# Generic_ARMv8MMainline register map
Vendor: ARM Ltd.; Series: ARMv8-M Mainline architecture (Cortex-M33 / Cortex-M35P / Cortex-M55 / Cortex-M85); File version: 1.0
CPU: CM33 r0p0, little endian, no MPU, no FPU, VTOR, 3 interrupt priority bits
Registers are 32-bit, read-write, reset 0x0 unless marked. A register's access mark holds for its fields unless they carry their own. Offsets are from the block's base; [hi:lo] are bit positions; {n}, {i} and the like mark numbered series; <NAME> marks a mode.

## SCB — System Control Block, ARMv8-M Mainline register set. Verified against CMSIS_6 core_cm33.h. Superset of ARMv7-M's SCB plus the Security Extension: NSACR (Non-secure Access Control), SFSR/SFAR (Secure Fault Status/Address -- physically the same registers CMSIS also exposes via SAU->SFSR/SFAR; modeled once here, under SCB, since SAU and SCB share the same 0xE000ED00-0xE000EDEF page -- see the two <addressBlock> entries below and the SAU peripheral's description), and extra ICSR/AIRCR/SCR/SHCSR/CFSR bits (see the individual register descriptions). ID_ISAR now has 6 words (ID_ISAR5 added) versus 5 on ARMv7-M; the ID_* register names themselves also changed (ADR/DFR -> ID_AFR/ID_DFR) to match current CMSIS naming for ARMv8-M. Deliberately excluded, same rationale as ARMv7-M: CFSR.MLSPERR/LSPERR (FPU lazy-stacking bits) are documented but the FPU block itself is not modeled, and the cache-maintenance registers present on cache-capable implementations (CLIDR/CTR/CCSIDR/CSSELR, ICIALLU..BPIALL, MVFR0-2, CCR.DC/IC/BP -- Cortex-M55/M85-specific) are out of scope, same as trace components (ITM/DWT/TPIU).
Base 0xE000ED00
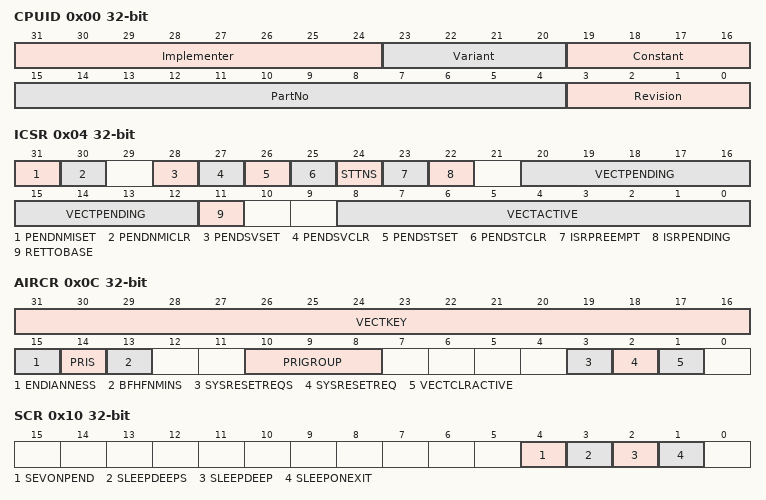
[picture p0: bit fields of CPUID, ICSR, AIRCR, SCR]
0x00 CPUID ro — CPUID Base Register. Reset value is implementation/revision specific.
  [31:24] Implementer — 0x41 = 'A' = ARM
  [23:20] Variant — Implementation specific variant number
  [19:16] Constant — Reads as 0xC for ARMv6-M, 0xF for ARMv7-M/ARMv8-M
  [15:4] PartNo — Implementation specific part number
  [3:0] Revision — Implementation/revision specific (e.g. r0p0 = 0x0)
0x04 ICSR — Interrupt Control and State Register
  [31] PENDNMISET — aka NMIPENDSET
  [30] PENDNMICLR wo — New in ARMv8-M
  [28] PENDSVSET
  [27] PENDSVCLR wo
  [26] PENDSTSET
  [25] PENDSTCLR wo
  [24] STTNS — Secure Transition To Non-secure -- Security Extension only, banked, RAZ/WI from Non-secure state
  [23] ISRPREEMPT ro
  [22] ISRPENDING ro
  [20:12] VECTPENDING
  [11] RETTOBASE ro
  [8:0] VECTACTIVE
0x08 VTOR — Vector Table Offset Register
  [31:7] TBLOFF
0x0C AIRCR — Application Interrupt and Reset Control Register
  [31:16] VECTKEY — Write 0x05FA to permit the write; reads as 0xFA05
  [15] ENDIANNESS ro — Renamed from ENDIANESS in CMSIS_6 (kept as a deprecated alias there)
  [14] PRIS — Prioritize Secure exceptions -- Security Extension only
  [13] BFHFNMINS — BusFault/HardFault/NMI target Non-secure state when set -- Security Extension only
  [10:8] PRIGROUP — Interrupt priority grouping
  [3] SYSRESETREQS — SYSRESETREQ traps to Secure state when set -- Security Extension only
  [2] SYSRESETREQ
  [1] VECTCLRACTIVE — Reserved for debug use
0x10 SCR — System Control Register
  [4] SEVONPEND
  [3] SLEEPDEEPS — SLEEPDEEP usable from Non-secure state -- Security Extension only
  [2] SLEEPDEEP
  [1] SLEEPONEXIT
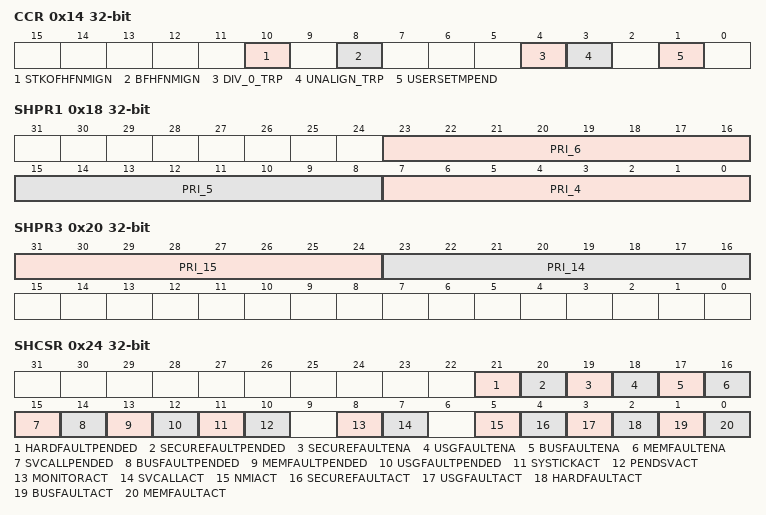
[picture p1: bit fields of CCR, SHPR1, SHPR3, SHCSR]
0x14 CCR — Configuration and Control Register
  [10] STKOFHFNMIGN — Ignore stack overflow while handling a HardFault/NMI/FAULTMASK-escalated fault -- new in ARMv8-M
  [8] BFHFNMIGN
  [4] DIV_0_TRP
  [3] UNALIGN_TRP
  [1] USERSETMPEND
0x18 SHPR1 — System Handler Priority Register 1
  [23:16] PRI_6 — UsageFault
  [15:8] PRI_5 — BusFault
  [7:0] PRI_4 — MemManage fault
0x1C SHPR2 — System Handler Priority Register 2
  [31:24] PRI_11 — SVCall
0x20 SHPR3 — System Handler Priority Register 3
  [31:24] PRI_15 — SysTick
  [23:16] PRI_14 — PendSV
0x24 SHCSR — System Handler Control and State Register
  [21] HARDFAULTPENDED — New in ARMv8-M
  [20] SECUREFAULTPENDED — Security Extension only
  [19] SECUREFAULTENA — Security Extension only
  [18] USGFAULTENA
  [17] BUSFAULTENA
  [16] MEMFAULTENA
  [15] SVCALLPENDED
  [14] BUSFAULTPENDED
  [13] MEMFAULTPENDED
  [12] USGFAULTPENDED
  [11] SYSTICKACT
  [10] PENDSVACT
  [8] MONITORACT
  [7] SVCALLACT
  [5] NMIACT — New in ARMv8-M
  [4] SECUREFAULTACT — Security Extension only
  [3] USGFAULTACT
  [2] HARDFAULTACT — New in ARMv8-M
  [1] BUSFAULTACT
  [0] MEMFAULTACT
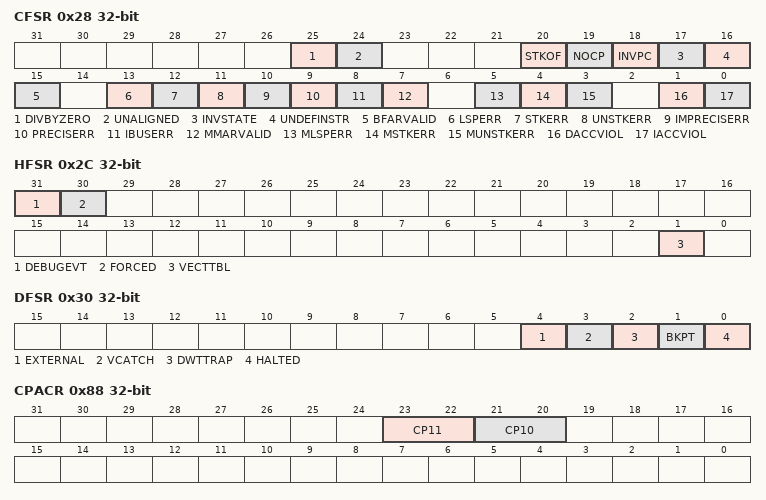
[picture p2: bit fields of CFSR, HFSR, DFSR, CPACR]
0x28 CFSR — Configurable Fault Status Register = MMFSR[7:0] | BFSR[15:8] | UFSR[31:16]
  [25] DIVBYZERO — UFSR
  [24] UNALIGNED — UFSR
  [20] STKOF — UFSR -- Stack Overflow, new in ARMv8-M
  [19] NOCP — UFSR
  [18] INVPC — UFSR
  [17] INVSTATE — UFSR
  [16] UNDEFINSTR — UFSR
  [15] BFARVALID ro — BFSR
  [13] LSPERR — BFSR -- lazy FP state preservation error, only meaningful with an FPU
  [12] STKERR — BFSR
  [11] UNSTKERR — BFSR
  [10] IMPRECISERR — BFSR
  [9] PRECISERR — BFSR
  [8] IBUSERR — BFSR
  [7] MMARVALID ro — MMFSR
  [5] MLSPERR — MMFSR -- lazy FP state preservation error, only meaningful with an FPU
  [4] MSTKERR — MMFSR
  [3] MUNSTKERR — MMFSR
  [1] DACCVIOL — MMFSR
  [0] IACCVIOL — MMFSR
0x2C HFSR — HardFault Status Register
  [31] DEBUGEVT, [30] FORCED, [1] VECTTBL
0x30 DFSR — Debug Fault Status Register
  [4] EXTERNAL, [3] VCATCH, [2] DWTTRAP, [1] BKPT, [0] HALTED
0x34 MMFAR — MemManage Fault Address Register, valid only when CFSR.MMARVALID is set
  [31:0] ADDRESS
0x38 BFAR — BusFault Address Register, valid only when CFSR.BFARVALID is set
  [31:0] ADDRESS
0x3C AFSR — Auxiliary Fault Status Register, implementation defined
  [31:0] IMPDEF
{0x40+4i} ID_PFR{i} (i=0..1) ro — Processor Feature Register, implementation defined
0x48 ID_DFR ro — Debug Feature Register, implementation defined
0x4C ID_AFR ro — Auxiliary Feature Register, implementation defined
{0x50+4i} ID_MMFR{i} (i=0..3) ro — Memory Model Feature Register, implementation defined
{0x60+4i} ID_ISAR{i} (i=0..5) ro — Instruction Set Attributes Register, implementation defined -- 6 words on ARMv8-M (ID_ISAR5 added), vs. 5 on ARMv7-M
0x88 CPACR — Coprocessor Access Control Register
  [23:22] CP11 — FPU access privileges -- only meaningful if an FPU is implemented
  [21:20] CP10 — FPU access privileges -- only meaningful if an FPU is implemented
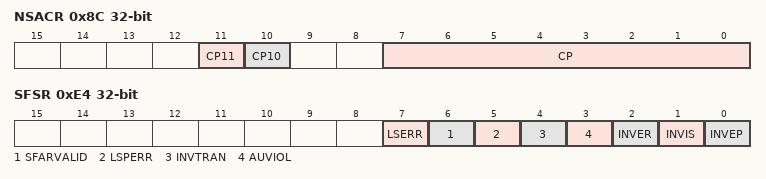
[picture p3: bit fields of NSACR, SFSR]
0x8C NSACR — Non-Secure Access Control Register -- Security Extension only
  [11] CP11 — Non-secure access permission for the FPU (CP11) -- Security Extension only, meaningful only if an FPU is implemented
  [10] CP10 — Non-secure access permission for the FPU (CP10) -- Security Extension only, meaningful only if an FPU is implemented
  [7:0] CP — Non-secure access permission for coprocessors CP0-CP7, one bit each -- Security Extension only
0xE4 SFSR — Secure Fault Status Register -- Security Extension only. Physically the same register as SAU->SFSR (CMSIS exposes it under both SCB_Type and SAU_Type).
  [7] LSERR
  [6] SFARVALID ro
  [5] LSPERR — Only meaningful with an FPU
  [4] INVTRAN
  [3] AUVIOL
  [2] INVER
  [1] INVIS
  [0] INVEP
0xE8 SFAR — Secure Fault Address Register, valid only when SFSR.SFARVALID is set -- Security Extension only. Physically the same register as SAU->SFAR.
  [31:0] ADDRESS
